VERSION ""

NS_ :

BS_:

BU_: airbagECU airbag
VAL_TABLE_ vtSig_airbagState 2 "Active" 1 "Inactive" 0 "Idle" ;

BO_ 1 SeatbeltSystem: 1 airbagECU
 SG_ SeatbeltState : 0|1@1+ (1,0) [0|0] "" Vector__XXX

BO_ 0 AirbagSystem: 2 airbagECU
 SG_ airbagState : 0|2@1+ (1,0) [0|2] "" Vector__XXX
 SG_ AirbagCondition : 2|1@1+ (1,0) [0|1] ""  Vector__XXX

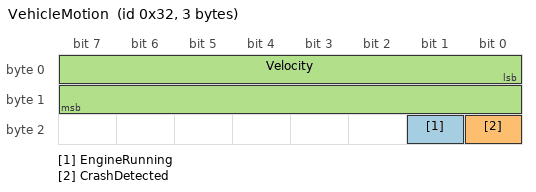
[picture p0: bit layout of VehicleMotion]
BO_ 50 VehicleMotion: 3 airbagECU
 SG_ EngineRunning : 17|1@1+ (1,0) [0|1] "" Vector__XXX
 SG_ CrashDetected : 16|1@1+ (1,0) [0|0] "" Vector__XXX
 SG_ Velocity : 0|16@1- (0.1,0) [-100|350] "km/h" Vector__XXX

BA_DEF_  "NmMessageCount" INT 0 0;
BA_DEF_ BO_  "GenMsgILSupport" ENUM  "No","Yes";
BA_DEF_  "NmBaseAddress" HEX 1024 1087;
BA_DEF_  "BusType" STRING ;
BA_DEF_ BO_  "GenMsgCycleTime" INT 0 50000;
BA_DEF_ BO_  "GenMsgSendType" ENUM  "Cyclic","NotUsed","NotUsed","NotUsed","NotUsed","Cyclic","NotUsed","IfActive","NoMsgSendType","NotUsed","vector_leerstring";
BA_DEF_ SG_  "GenSigSendType" ENUM  "Cyclic","OnWrite","OnWriteWithRepetition","OnChange","OnChangeWithRepetition","IfActive","IfActiveWithRepetition","NoSigSendType","NotUsed","NotUsed","NotUsed","NotUsed","NotUsed";
BA_DEF_DEF_  "NmMessageCount" 64;
BA_DEF_DEF_  "GenMsgILSupport" "Yes";
BA_DEF_DEF_  "NmBaseAddress" 1024;
BA_DEF_DEF_  "BusType" "CAN";
BA_DEF_DEF_  "GenMsgCycleTime" 100;
BA_DEF_DEF_  "GenMsgSendType" "NoMsgSendType";
BA_DEF_DEF_  "GenSigSendType" "Cyclic";
BA_ "GenSigSendType" SG_ 50 CrashDetected 1;
VAL_ 0 airbagState 2 "Active" 1 "Inactive" 0 "Idle" ;
